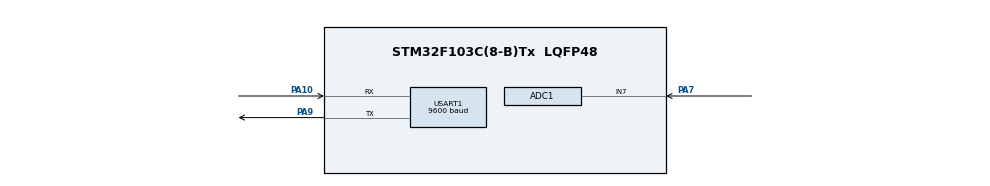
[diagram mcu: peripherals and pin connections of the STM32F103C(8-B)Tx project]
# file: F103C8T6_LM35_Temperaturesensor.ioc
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ADC1.Channel-0\#ChannelRegularConversion=ADC_CHANNEL_7
ADC1.ContinuousConvMode=ENABLE
ADC1.NbrOfConversionFlag=1
ADC1.Rank-0\#ChannelRegularConversion=1
ADC1.SamplingTime-0\#ChannelRegularConversion=ADC_SAMPLETIME_239CYCLES_5
ADC1.master=1
Mcu.Family=STM32F1
Mcu.Name=STM32F103C(8-B)Tx
Mcu.Package=LQFP48
NVIC.PriorityGroup=NVIC_PRIORITYGROUP_4
PA10.Mode=Asynchronous
PA10.Signal=USART1_RX
PA13.Mode=Serial_Wire
PA13.Signal=SYS_JTMS-SWDIO
PA14.Mode=Serial_Wire
PA14.Signal=SYS_JTCK-SWCLK
PA7.Signal=ADCx_IN7
PA9.Mode=Asynchronous
PA9.Signal=USART1_TX
PD0-OSC_IN.Mode=HSE-External-Oscillator
PD0-OSC_IN.Signal=RCC_OSC_IN
PD1-OSC_OUT.Mode=HSE-External-Oscillator
PD1-OSC_OUT.Signal=RCC_OSC_OUT
ProjectManager.HeapSize=0x200
ProjectManager.StackSize=0x400
ProjectManager.TargetToolchain=STM32CubeIDE
RCC.APB1Freq_Value=8000000
RCC.APB2Freq_Value=8000000
SH.ADCx_IN7.0=ADC1_IN7,IN7
USART1.BaudRate=9600
USART1.VirtualMode=VM_ASYNC
board=custom

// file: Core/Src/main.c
/* USER CODE BEGIN Header */
/**
 ******************************************************************************
 * @file           : main.c
 * @brief          : Main program body
 ******************************************************************************
 * @attention
 *
 * Copyright (c) 2025 STMicroelectronics.
 * All rights reserved.
 *
 * This software is licensed under terms that can be found in the LICENSE file
 * in the root directory of this software component.
 * If no LICENSE file comes with this software, it is provided AS-IS.
 *
 ******************************************************************************
 */
/* USER CODE END Header */
#include "main.h"
#include <stdio.h>
#include <string.h>

ADC_HandleTypeDef hadc1;

UART_HandleTypeDef huart1;

void SystemClock_Config(void);
static void MX_GPIO_Init(void);
static void MX_ADC1_Init(void);
static void MX_USART1_UART_Init(void);
/* USER CODE BEGIN PFP */
char uart_buf[50];
uint16_t adc_value = 0;
float tempC = 0;
/* USER CODE END PFP */

int main(void) {

	/* MCU Configuration--------------------------------------------------------*/

	/* Reset of all peripherals, Initializes the Flash interface and the Systick. */
	HAL_Init();

	/* Configure the system clock */
	SystemClock_Config();

	/* Initialize all configured peripherals */
	MX_GPIO_Init();
	MX_ADC1_Init();
	MX_USART1_UART_Init();
	/* USER CODE BEGIN 2 */
	HAL_ADC_Start(&hadc1);
	/* USER CODE END 2 */

	/* Infinite loop */
	while (1) {
		adc_value = HAL_ADC_GetValue(&hadc1);

		// Convert ADC value to temperature (assuming 5V Vref)
		tempC = ((float) adc_value * 3.3f / 4095.0f) * 100.0f;

		// Format and send temperature string
		sprintf(uart_buf, "Temperature: %.2f°C\r\n", tempC);
		HAL_UART_Transmit(&huart1, (uint8_t*) uart_buf, strlen(uart_buf),
				HAL_MAX_DELAY);

		HAL_Delay(1000);
	}
}

void SystemClock_Config(void) {
	RCC_OscInitTypeDef RCC_OscInitStruct = { 0 };
	RCC_ClkInitTypeDef RCC_ClkInitStruct = { 0 };
	RCC_PeriphCLKInitTypeDef PeriphClkInit = { 0 };

	/** Initializes the RCC Oscillators according to the specified parameters
	 * in the RCC_OscInitTypeDef structure.
	 */
	RCC_OscInitStruct.OscillatorType = RCC_OSCILLATORTYPE_HSI;
	RCC_OscInitStruct.HSIState = RCC_HSI_ON;
	RCC_OscInitStruct.HSICalibrationValue = RCC_HSICALIBRATION_DEFAULT;
	RCC_OscInitStruct.PLL.PLLState = RCC_PLL_NONE;
	if (HAL_RCC_OscConfig(&RCC_OscInitStruct) != HAL_OK) {
		Error_Handler();
	}

	/** Initializes the CPU, AHB and APB buses clocks
	 */
	RCC_ClkInitStruct.ClockType = RCC_CLOCKTYPE_HCLK | RCC_CLOCKTYPE_SYSCLK
			| RCC_CLOCKTYPE_PCLK1 | RCC_CLOCKTYPE_PCLK2;
	RCC_ClkInitStruct.SYSCLKSource = RCC_SYSCLKSOURCE_HSI;
	RCC_ClkInitStruct.AHBCLKDivider = RCC_SYSCLK_DIV1;
	RCC_ClkInitStruct.APB1CLKDivider = RCC_HCLK_DIV1;
	RCC_ClkInitStruct.APB2CLKDivider = RCC_HCLK_DIV1;

	if (HAL_RCC_ClockConfig(&RCC_ClkInitStruct, FLASH_LATENCY_0) != HAL_OK) {
		Error_Handler();
	}
	PeriphClkInit.PeriphClockSelection = RCC_PERIPHCLK_ADC;
	PeriphClkInit.AdcClockSelection = RCC_ADCPCLK2_DIV2;
	if (HAL_RCCEx_PeriphCLKConfig(&PeriphClkInit) != HAL_OK) {
		Error_Handler();
	}
}

static void MX_ADC1_Init(void) {

	ADC_ChannelConfTypeDef sConfig = { 0 };

	/** Common config
	 */
	hadc1.Instance = ADC1;
	hadc1.Init.ScanConvMode = ADC_SCAN_DISABLE;
	hadc1.Init.ContinuousConvMode = ENABLE;
	hadc1.Init.DiscontinuousConvMode = DISABLE;
	hadc1.Init.ExternalTrigConv = ADC_SOFTWARE_START;
	hadc1.Init.DataAlign = ADC_DATAALIGN_RIGHT;
	hadc1.Init.NbrOfConversion = 1;
	if (HAL_ADC_Init(&hadc1) != HAL_OK) {
		Error_Handler();
	}

	/** Configure Regular Channel
	 */
	sConfig.Channel = ADC_CHANNEL_7;
	sConfig.Rank = ADC_REGULAR_RANK_1;
	sConfig.SamplingTime = ADC_SAMPLETIME_239CYCLES_5;
	if (HAL_ADC_ConfigChannel(&hadc1, &sConfig) != HAL_OK) {
		Error_Handler();
	}

}

static void MX_USART1_UART_Init(void) {

	huart1.Instance = USART1;
	huart1.Init.BaudRate = 9600;
	huart1.Init.WordLength = UART_WORDLENGTH_8B;
	huart1.Init.StopBits = UART_STOPBITS_1;
	huart1.Init.Parity = UART_PARITY_NONE;
	huart1.Init.Mode = UART_MODE_TX_RX;
	huart1.Init.HwFlowCtl = UART_HWCONTROL_NONE;
	huart1.Init.OverSampling = UART_OVERSAMPLING_16;
	if (HAL_UART_Init(&huart1) != HAL_OK) {
		Error_Handler();
	}

}

static void MX_GPIO_Init(void) {

	/* GPIO Ports Clock Enable */
	__HAL_RCC_GPIOD_CLK_ENABLE();
	__HAL_RCC_GPIOA_CLK_ENABLE();

}

void Error_Handler(void) {
	__disable_irq();
	while (1) {
	}
}
